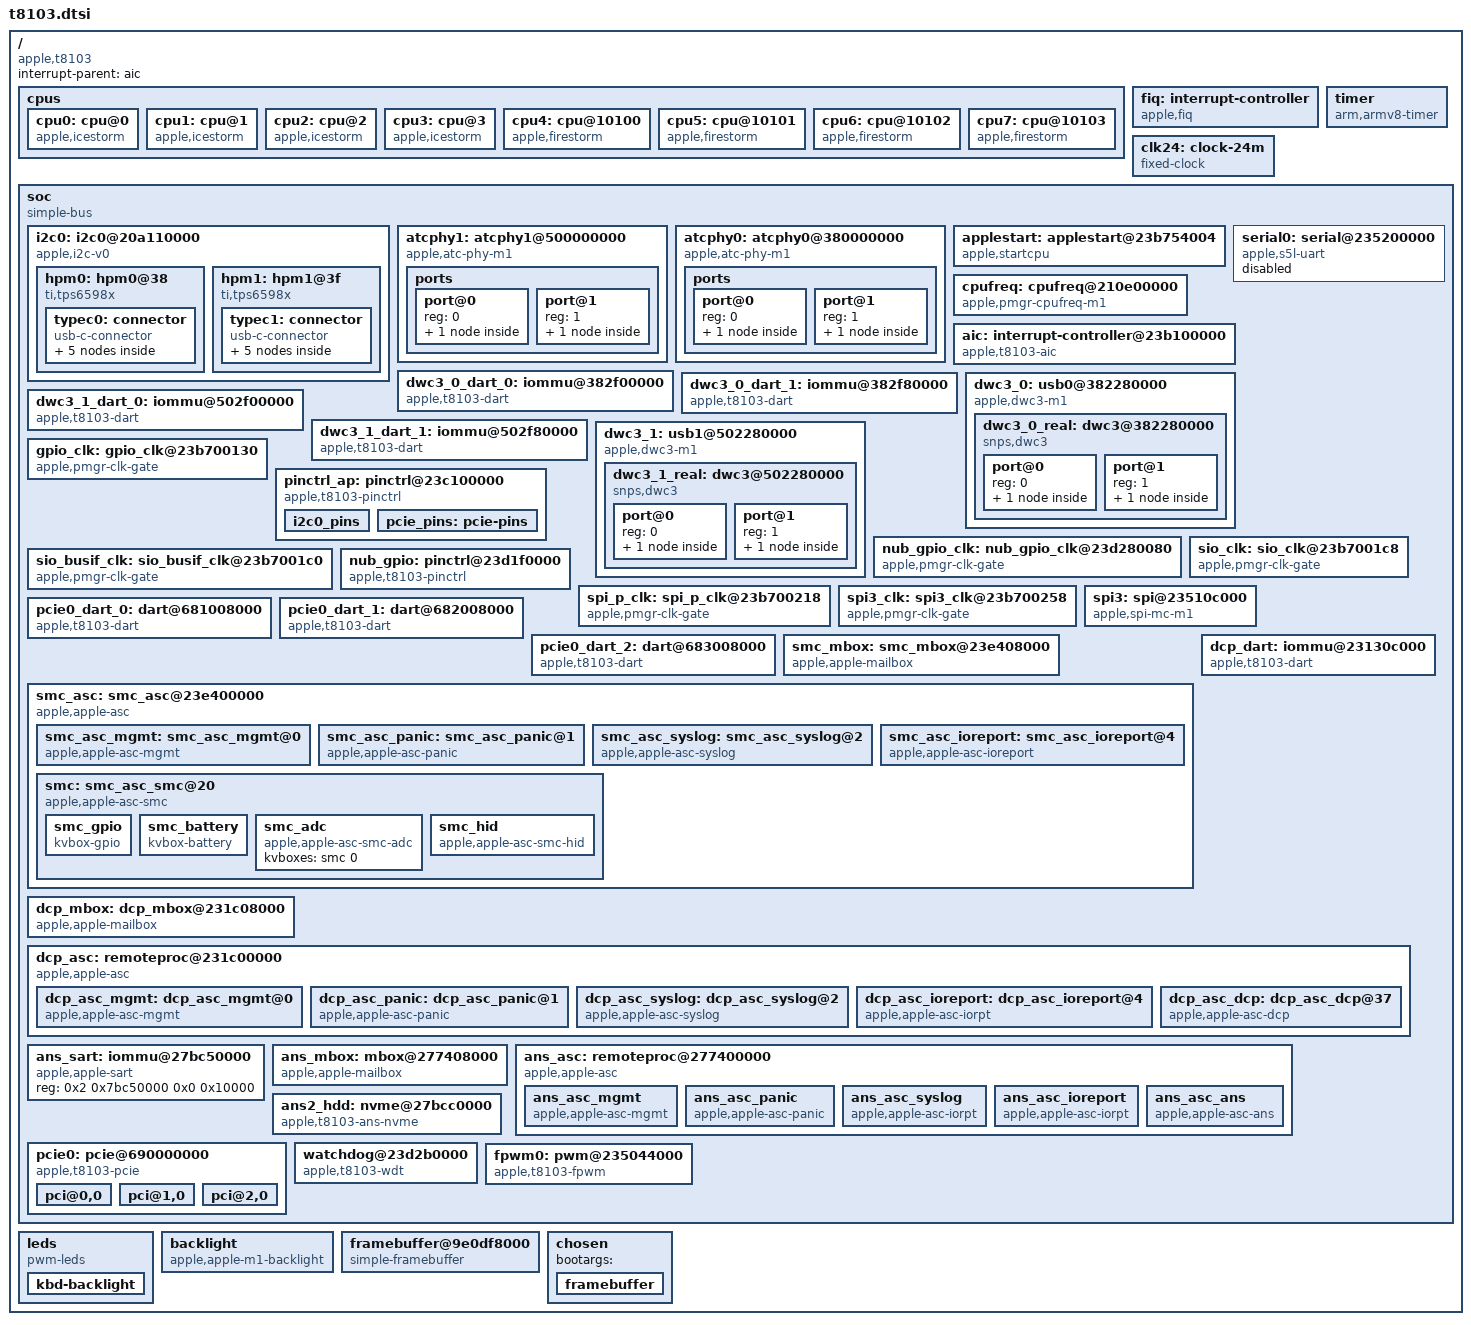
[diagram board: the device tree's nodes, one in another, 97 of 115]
// SPDX-License-Identifier: GPL-2.0+ OR MIT
/*
 * Apple T8103 "M1" SoC
 *
 * Other names: H13G, "Tonga"
 *
 * Copyright The Asahi Linux Contributors
 */

#include <dt-bindings/soc/ascii.h>
#include <dt-bindings/interrupt-controller/apple-aic.h>
#include <dt-bindings/interrupt-controller/irq.h>

#define APPLE_PINMUX(pin, func) ((pin) | ((func) << 16))
#define APPLE_PIN(pinmux) ((pinmux) & 0xffff)
#define APPLE_FUNC(pinmux) ((pinmux) >> 16)

/ {
	compatible = "apple,t8103", "apple,arm-platform";

	#address-cells = <2>;
	#size-cells = <2>;
	interrupt-parent = <&aic>;

	cpus {
		#address-cells = <1>;
		#size-cells = <0>;

		cpu0: cpu@0 {
			compatible = "apple,icestorm";
			device_type = "cpu";
			reg = <0x0>;
			enable-method = "apple,startcpu";
			cpu-release-addr = <0 0>; /* To be filled by loader */
			apple,cluster = <0>;
		};

		cpu1: cpu@1 {
			compatible = "apple,icestorm";
			device_type = "cpu";
			reg = <0x1>;
			enable-method = "apple,startcpu";
			cpu-release-addr = <0 0>; /* To be filled by loader */
			apple,cluster = <0>;
		};

		cpu2: cpu@2 {
			compatible = "apple,icestorm";
			device_type = "cpu";
			reg = <0x2>;
			enable-method = "apple,startcpu";
			cpu-release-addr = <0 0>; /* To be filled by loader */
			apple,cluster = <0>;
		};

		cpu3: cpu@3 {
			compatible = "apple,icestorm";
			device_type = "cpu";
			reg = <0x3>;
			enable-method = "apple,startcpu";
			cpu-release-addr = <0 0>; /* To be filled by loader */
			apple,cluster = <0>;
		};

		cpu4: cpu@10100 {
			compatible = "apple,firestorm";
			device_type = "cpu";
			reg = <0x10100>;
			enable-method = "apple,startcpu";
			cpu-release-addr = <0 0>; /* To be filled by loader */
			apple,cluster = <1>;
		};

		cpu5: cpu@10101 {
			compatible = "apple,firestorm";
			device_type = "cpu";
			reg = <0x10101>;
			enable-method = "apple,startcpu";
			cpu-release-addr = <0 0>; /* To be filled by loader */
			apple,cluster = <1>;
		};

		cpu6: cpu@10102 {
			compatible = "apple,firestorm";
			device_type = "cpu";
			reg = <0x10102>;
			enable-method = "apple,startcpu";
			cpu-release-addr = <0 0>; /* To be filled by loader */
			apple,cluster = <1>;
		};

		cpu7: cpu@10103 {
			compatible = "apple,firestorm";
			device_type = "cpu";
			reg = <0x10103>;
			enable-method = "apple,startcpu";
			cpu-release-addr = <0 0>; /* To be filled by loader */
			apple,cluster = <1>;
		};
	};

	fiq: interrupt-controller {
	        compatible = "apple,fiq";
		#interrupt-cells = <3>;
		interrupt-controller;
		use-for-ipi;
	};

	timer {
		compatible = "arm,armv8-timer";
		interrupt-parent = <&fiq>;
		interrupt-names = "phys", "virt", "hyp-phys", "hyp-virt";
		interrupts = <AIC_FIQ AIC_TMR_GUEST_PHYS IRQ_TYPE_LEVEL_HIGH>,
			     <AIC_FIQ AIC_TMR_GUEST_VIRT IRQ_TYPE_LEVEL_HIGH>,
			     <AIC_FIQ AIC_TMR_HV_PHYS IRQ_TYPE_LEVEL_HIGH>,
			     <AIC_FIQ AIC_TMR_HV_VIRT IRQ_TYPE_LEVEL_HIGH>;
	};

	clk24: clock-24m {
		compatible = "fixed-clock";
		#clock-cells = <0>;
		clock-frequency = <24000000>;
		clock-output-names = "clk24";
	};

	soc {
		compatible = "simple-bus";
		#address-cells = <2>;
		#size-cells = <2>;

		ranges;
		dma-ranges;
		nonposted-mmio;

		i2c0: i2c0@20a110000 {
			compatible = "apple,i2c-v0";
			reg = <0x2 0x35010000 0x0 0x4000>;
			interrupt-parent = <&aic>;
			interrupts = <0 627 4>;
			clocks = <&clk24>;
			pinctrl-0 = <&i2c0_pins>;
			pinctrl-names = "default";
			#address-cells = <0x1>;
			#size-cells = <0x0>;

			hpm0: hpm0@38 {
				compatible = "ti,tps6598x";
				reg = <0x38>;
				interrupt-parent = <&pinctrl_ap>;
				interrupts = <106 8>;

				no-long-writes;

				typec0: connector {
					compatible = "usb-c-connector";
					label = "USB-C B";
					power-role = "source";

					ports {
						#address-cells = <1>;
						#size-cells = <0>;
						port@0 {
							reg = <0>;
							typec0_con_hs: endpoint {
								remote-endpoint = <&typec0_usb_hs>;
							};
						};
						port@1 {
							reg = <1>;
							typec0_con_ss: endpoint {
								remote-endpoint = <&typec0_phy_ss>;
							};
						};
					};
				};
			};

			hpm1: hpm1@3f {
				compatible = "ti,tps6598x";
				reg = <0x3f>;
				interrupt-parent = <&pinctrl_ap>;
				interrupts = <106 8>;

				no-long-writes;

				typec1: connector {
					compatible = "usb-c-connector";
					label = "USB-C B";
					power-role = "source";

					ports {
						#address-cells = <1>;
						#size-cells = <0>;
						port@0 {
							reg = <0>;
							typec1_con_hs: endpoint {
								remote-endpoint = <&typec1_usb_hs>;
							};
						};
						port@1 {
							reg = <1>;
							typec1_con_ss: endpoint {
								remote-endpoint = <&typec1_phy_ss>;
							};
						};
					};
				};
			};
		};

		atcphy1: atcphy1@500000000 {
			compatible = "apple,atc-phy-m1";
			clocks = <&clk24>;
			reg = <0x5 0x00000000 0x0 0x1000000
				0x5 0x02000000 0x0 0x1080000>;
			#phy-cells = <0>;
			usb-role-switch;
			orientation-switch;
			mode-switch;
			accessory;
			#clock-cells = <0>;
			clock-output-names = "utmi1clk";

			ports {
				#address-cells = <1>;
				#size-cells = <0>;
				port@0 {
					reg = <0>;
					typec1_phy_ss: endpoint {
						phandle = <0x0e>;
					};
				};
				port@1 {
					reg = <1>;
					typec1_pipe_ss: endpoint {
						phandle = <0x2f>;
					};
				};
			};
		};


        atcphy0: atcphy0@380000000 {
            compatible = "apple,atc-phy-m1";
            clocks = <&clk24>;
            reg = <0x3 0x80000000 0x0 0x1000000
                   0x3 0x82000000 0x0 0x1080000>;
            #phy-cells = <0>;
            usb-role-switch;
            orientation-switch;
            mode-switch;
            accessory;
            #clock-cells = <0>;
            clock-output-names = "utmi0clk";

            ports {
                #address-cells = <1>;
                #size-cells = <0>;
                port@0 {
                    reg = <0>;
                    typec0_phy_ss: endpoint {
		    	phandle = <0x0f>;
                    };
                };
                port@1 {
                    reg = <1>;
                    typec0_pipe_ss: endpoint {
		    	phandle = <0x2e>;
                    };
                };
            };
        };
		applestart: applestart@23b754004 {
			compatible = "apple,startcpu";
			reg = <0x2 0x3b754004 0x0 0xc   0x2 0x10050000 0x0 0x8   0x2 0x10030fb0 0x0 0x4
				0x2 0x3b754004 0x0 0xc   0x2 0x10150000 0x0 0x8   0x2 0x10130fb0 0x0 0x4
				0x2 0x3b754004 0x0 0xc   0x2 0x10250000 0x0 0x8   0x2 0x10230fb0 0x0 0x4
				0x2 0x3b754004 0x0 0xc   0x2 0x10350000 0x0 0x8   0x2 0x10330fb0 0x0 0x4
				0x2 0x3b754004 0x0 0xc   0x2 0x11050000 0x0 0x8   0x2 0x11030fb0 0x0 0x4
				0x2 0x3b754004 0x0 0xc   0x2 0x11150000 0x0 0x8   0x2 0x11130fb0 0x0 0x4
				0x2 0x3b754004 0x0 0xc   0x2 0x11250000 0x0 0x8   0x2 0x11230fb0 0x0 0x4
				0x2 0x3b754004 0x0 0xc   0x2 0x11350000 0x0 0x8   0x2 0x11330fb0 0x0 0x4>;
		};

		cpufreq: cpufreq@210e00000 {
			compatible = "apple,pmgr-cpufreq-m1";
			reg = <0x2 0x10e00000 0x0 0x100000   0x2 0x11e00000 0x0 0x100000
				0x2 0x3b700000 0x0 0x100000   0x2 0x00200000 0x0 0x200000>;
			tunable-ecpu-states = <0x1aaaa 0x22c 0x1075f 0x26d 0xc031 0x2a6 0x963c 0x300 0x7c07 0x35b>;
			tunable-pcpu-states = <0x1aaaa 0x254 0x1352d 0x27d 0xf26c 0x2a3 0xc760 0x2a9 0xaaaa 0x2d1 0x9425 0x2e4 0x82e1 0x310 0x7537 0x320 0x6b33 0x342 0x62c3 0x377 0x5c5a 0x3a0 0x55ad 0x3d2 0x52af 0x3d2 0x516c 0x3d2 0x4fe6 0x3d2>;
			tunable-pcpu-fast-dcfg = <0x133 0x55555340>;
			tunable-pcpu-fast-freq = <0x888>;
		};

		serial0: serial@235200000 {
			compatible = "apple,s5l-uart";
			reg = <0x2 0x35200000 0x0 0x1000>;
			reg-io-width = <4>;
			interrupt-parent = <&aic>;
			interrupts = <AIC_IRQ 605 IRQ_TYPE_LEVEL_HIGH>;
			/*
			 * TODO: figure out the clocking properly, there may
			 * be a third selectable clock.
			 */
			clocks = <&clk24>, <&clk24>;
			clock-names = "uart", "clk_uart_baud0";
			status = "disabled";
		};

		aic: interrupt-controller@23b100000 {
			compatible = "apple,t8103-aic";
			#interrupt-cells = <3>;
			interrupt-controller;
			reg = <0x2 0x3b100000 0x0 0x8000>;
		};

		dwc3_0_dart_0: iommu@382f00000 {
			compatible = "apple,t8103-dart";
			reg = <0x3 0x82f00000 0x0 0x4000>;
			interrupt-parent = <&aic>;
			interrupts = <AIC_IRQ 781 IRQ_TYPE_LEVEL_HIGH>;
			#iommu-cells = <1>;
		};

		dwc3_0_dart_1: iommu@382f80000 {
			compatible = "apple,t8103-dart";
			reg = <0x3 0x82f80000 0x0 0x4000>;
			interrupt-parent = <&aic>;
			interrupts = <AIC_IRQ 781 IRQ_TYPE_LEVEL_HIGH>;
			#iommu-cells = <1>;
		};

		dwc3_0: usb0@382280000 {
			compatible = "apple,dwc3-m1";
			reg = <0x3 0x80000000 0x0 0x100000 0x3 0x82000000 0x0 0x1000000>;
			#address-cells = <2>;
			#size-cells = <2>;
			ranges;
			nonposted-mmio;
			usb-role-switch;

			dwc3_0_real: dwc3@382280000 {
				compatible = "snps,dwc3";
				reg = <0x3 0x82280000 0x0 0x100000>;
				interrupt-parent = <&aic>;
				interrupts = <AIC_IRQ 777 IRQ_TYPE_LEVEL_HIGH>;
				usb-role-switch;
				iommus = <&dwc3_0_dart_0 0>, <&dwc3_0_dart_1 1>;
				port@0 {
					reg = <0>;
					typec0_usb_hs: endpoint {
						remote-endpoint = <&typec0_con_hs>;
					};
				};
				port@1 {
					reg = <1>;
					typec0_usb_ss: endpoint {
						remote-endpoint = <&typec0_pipe_ss>;
					};
				};
			};
		};

		dwc3_1_dart_0: iommu@502f00000 {
			compatible = "apple,t8103-dart";
			reg = <0x5 0x02f00000 0x0 0x4000>;
			interrupt-parent = <&aic>;
			interrupts = <AIC_IRQ 861 IRQ_TYPE_LEVEL_HIGH>;
			#iommu-cells = <1>;
		};

		dwc3_1_dart_1: iommu@502f80000 {
			compatible = "apple,t8103-dart";
			reg = <0x5 0x02f80000 0x0 0x4000>;
			interrupt-parent = <&aic>;
			interrupts = <AIC_IRQ 861 IRQ_TYPE_LEVEL_HIGH>;
			#iommu-cells = <1>;
		};

		dwc3_1: usb1@502280000 {
			compatible = "apple,dwc3-m1";
			reg = <0x5 0x00000000 0x0 0x100000 0x5 0x02000000 0x0 0x1000000>;
			#address-cells = <2>;
			#size-cells = <2>;
			ranges;
			nonposted-mmio;
			usb-role-switch;

			dwc3_1_real: dwc3@502280000 {
				compatible = "snps,dwc3";
				reg = <0x5 0x02280000 0x0 0x100000>;
				interrupt-parent = <&aic>;
				interrupts = <AIC_IRQ 857 IRQ_TYPE_LEVEL_HIGH>;
				iommus = <&dwc3_1_dart_0 0>, <&dwc3_1_dart_1 1>;
				usb-role-switch;
				port@0 {
					reg = <0>;
					typec1_usb_hs: endpoint {
						remote-endpoint = <&typec1_con_hs>;
					};
				};
				port@1 {
					reg = <1>;
					typec1_usb_ss: endpoint {
						remote-endpoint = <&typec1_pipe_ss>;
					};
				};
			};
		};

		gpio_clk: gpio_clk@23b700130 {
		    compatible = "apple,pmgr-clk-gate";
		    #clock-cells = <0>;
		    reg = <0x2 0x3b700130 0x0 0x8>;
		    clocks = <&clk24>;
		    clock-output-names = "gpio_clk";
		};

		pinctrl_ap: pinctrl@23c100000 {
			compatible = "apple,t8103-pinctrl", "apple,pinctrl";
			reg = <0x2 0x3c100000 0x0 0x100000>;
		    pin-count = <212>;

		    interrupts = <0 190 4   0 191 4   0 192 4   0 193 4   0 194 4   0 195 4   0 196 4>;

		    clocks = <&gpio_clk>;

		    gpio-controller;
		    #gpio-cells = <2>;
		    gpio-ranges = <&pinctrl_ap 0 0 212>;

                    interrupt-parent = <&aic>;
		    interrupt-controller;
		    #interrupt-cells = <2>;

		    i2c0_pins: i2c0_pins {
		        pinmux = <APPLE_PINMUX(192, 1) APPLE_PINMUX(188, 1)>;
		    };

			pcie_pins: pcie-pins {
				pinmux = <APPLE_PINMUX(150, 1)>,
					 <APPLE_PINMUX(151, 1)>,
					 <APPLE_PINMUX(32, 1)>;
			};
		};

		nub_gpio_clk: nub_gpio_clk@23d280080 {
		    compatible = "apple,pmgr-clk-gate";
		    #clock-cells = <0>;
		    reg = <0x2 0x3d280080 0x0 0x8>;
		    clocks = <&clk24>;
		    clock-output-names = "nub_gpio_clk";
		};

		sio_busif_clk: sio_busif_clk@23b7001c0 {
			compatible = "apple,pmgr-clk-gate";
			#clock-cells = <0>;
			reg = <0x2 0x3b7001c0 0x0 0x8>;
			clocks = <&clk24>;
			clock-output-names = "sio_busif_clk";
		};

		sio_clk: sio_clk@23b7001c8 {
			compatible = "apple,pmgr-clk-gate";
			#clock-cells = <0>;
			reg = <0x2 0x3b7001c8 0x0 0x8>;
			clocks = <&sio_busif_clk>;
			clock-output-names = "sio_clk";
		};

		nub_gpio: pinctrl@23d1f0000 {
		    compatible = "apple,t8103-pinctrl", "apple,pinctrl";
		    reg = <0x2 0x3d1f0000 0x0 0x4000>;

			interrupts = <AIC_IRQ 330 IRQ_TYPE_LEVEL_HIGH
			              AIC_IRQ 331 IRQ_TYPE_LEVEL_HIGH
			              AIC_IRQ 332 IRQ_TYPE_LEVEL_HIGH
			              AIC_IRQ 333 IRQ_TYPE_LEVEL_HIGH
			              AIC_IRQ 334 IRQ_TYPE_LEVEL_HIGH
			              AIC_IRQ 335 IRQ_TYPE_LEVEL_HIGH
			              AIC_IRQ 336 IRQ_TYPE_LEVEL_HIGH>;

		    clocks = <&nub_gpio_clk>;

		    gpio-controller;
		    #gpio-cells = <2>;
		    gpio-ranges = <&nub_gpio 0 221 23>;

                    interrupt-parent = <&aic>;
		    interrupt-controller;
		    #interrupt-cells = <2>;
		};

		spi_p_clk: spi_p_clk@23b700218 {
		    compatible = "apple,pmgr-clk-gate";
		    #clock-cells = <0>;
		    reg = <0x2 0x3b700218 0x0 0x8>;
		    clocks = <&sio_clk>;
		    clock-output-names = "spi_p_clk";
		};

		spi3_clk: spi3_clk@23b700258 {
		    compatible = "apple,pmgr-clk-gate";
		    #clock-cells = <0>;
		    reg = <0x2 0x3b700258 0x0 0x8>;
		    clocks = <&spi_p_clk>;
		    clock-output-names = "spi3_clk";
		};

		spi3: spi@23510c000 {
		    compatible = "apple,spi-mc-m1";
		    reg = <0x2 0x3510c000 0x0 0x4000>;
		    interrupts = <0 617 4>;
		    //clocks = <&spi3_clk>;
                    interrupt-parent = <&aic>;
                    clocks = <&clk24>;
		    cs-gpios = <&pinctrl_ap 49 0>;
		    #address-cells = <1>;
		    #size-cells = <0>;
		};

		pcie0_dart_0: dart@681008000 {
			compatible = "apple,t8103-dart";
			reg = <0x6 0x81008000 0x0 0x4000>;
			#iommu-cells = <1>;
			interrupt-parent = <&aic>;
			interrupts = <AIC_IRQ 696 IRQ_TYPE_LEVEL_HIGH>;
		};

		pcie0_dart_1: dart@682008000 {
			compatible = "apple,t8103-dart";
			reg = <0x6 0x82008000 0x0 0x4000>;
			#iommu-cells = <1>;
			interrupt-parent = <&aic>;
			interrupts = <AIC_IRQ 699 IRQ_TYPE_LEVEL_HIGH>;
		};

		pcie0_dart_2: dart@683008000 {
			compatible = "apple,t8103-dart";
			reg = <0x6 0x83008000 0x0 0x4000>;
			#iommu-cells = <1>;
			interrupt-parent = <&aic>;
			interrupts = <AIC_IRQ 702 IRQ_TYPE_LEVEL_HIGH>;
		};

		smc_mbox: smc_mbox@23e408000 {
		        compatible = "apple,apple-mailbox";
			reg = <0x2 0x3e408000 0 0x4000>;
			#mbox-cells = <1>; /* could be 0, but that requires extra code */
			interrupt-parent = <&aic>;
			interrupts = <0 400 4  0 403 4>;
		};

		smc_asc: smc_asc@23e400000 {
		        compatible = "apple,apple-asc";
			reg = <0x2 0x3e400000 0 0x8000>;
			rproc-name = "smc";
			mboxes = <&smc_mbox 0>;
			#mbox-cells = <1>;
			endpoints = <0>;
			smc_asc_mgmt: smc_asc_mgmt@0 {
				compatible = "apple,apple-asc-mgmt", "apple,apple-asc-system-endpoint";
				mboxes = <&smc_asc 0x0>;
				rprocs = <&smc_asc>;
			};
			smc_asc_panic: smc_asc_panic@1 {
				compatible = "apple,apple-asc-panic", "apple,apple-asc-system-endpoint";
				mboxes = <&smc_asc 0x1>;
				rprocs = <&smc_asc>;
			};
			smc_asc_syslog: smc_asc_syslog@2 {
				compatible = "apple,apple-asc-syslog", "apple,apple-asc-system-endpoint";
				mboxes = <&smc_asc 0x2>;
				rprocs = <&smc_asc>;
			};
			smc_asc_ioreport: smc_asc_ioreport@4 {
				compatible = "apple,apple-asc-ioreport", "apple,apple-asc-system-endpoint";
				mboxes = <&smc_asc 0x4>;
				rprocs = <&smc_asc>;
			};
			smc: smc_asc_smc@20 {
			        compatible = "apple,apple-asc-smc";
				mboxes = <&smc_asc 0x20>;
				rprocs = <&smc_asc>;
				#address-cells = <1>;
				#size-cells = <1>;
				#kvbox-cells = <1>;
				#mbox-cells = <1>;
				smc_gpio: smc_gpio {
					pin-count = <2>;
					pin-prefix = "smc";
					compatible = "kvbox-gpio";
					kvboxes = <&smc 0>;
					kvbox-keys = "gP0d", "gP12";
					kvbox-read-suffix = /bits/ 8 <0x01 0x00 0x00 0x00>;
					kvbox-write-enable = /bits/ 8 <0x01 0x00 0x80 0x00>;
					kvbox-write-disable = /bits/ 8 <0x00 0x00 0x00 0x00>;
					gpio-line-names = "gP0d", "gP12";
				        gpio-controller;
					#gpio-cells = <2>;

#define SMC_IRQ_BATT 0
#define SMC_IRQ_HID 1

#define SMC_PIN(a,b,c,d,description) \
	pin_##a##b##c##d { \
		gpio-line-name = description; \
	        key-read = /bits/ 8 <ASCII_##d ASCII_##c ASCII_##b ASCII_##a 0x01 0x00 0x00 0x00>; \
	        key-write = /bits/ 8 <ASCII_##d ASCII_##c ASCII_##b ASCII_##a>; \
	        data-enable = /bits/ 8 <0x01 0x00 0x00 0x00>; \
	        data-disable = /bits/ 8 <0x00 0x00 0x00 0x00>; \
	}
	     		      		SMC_PIN(g,P,0,d,"PCI power");
					SMC_PIN(g,P,1,2,"backlight power");
				};
				smc_battery {
					compatible = "kvbox-battery";
					mboxes = <&smc 1>;
					kvboxes = <&smc 0>;

					capacity-prop = <FOURCC(S,B,A,S)>;
				};
				smc_adc {
					compatible = "apple,apple-asc-smc-adc";
					kvboxes = <&smc 0>;
					#kvbox-cells = <1>;
				};
				smc_hid {
					compatible = "apple,apple-asc-smc-hid";
					mboxes = <&smc 0>;
					kvboxes = <&smc 0>;
				};
			};
		};

		dcp_mbox: dcp_mbox@231c08000 {
		        compatible = "apple,apple-mailbox";
			reg = <0x2 0x31c08000 0 0x4000>;
			#mbox-cells = <1>; /* could be 0, but that requires extra code */
			interrupt-parent = <&aic>;
			interrupts = <0 0x1ab 4  0 0x1ae 4>;
		};

		dcp_dart: iommu@23130c000 {
			compatible = "apple,t8103-dart";
			reg = <0x2 0x3130c000 0 0x4000>;
			interrupt-parent = <&aic>;
			interrupts = <AIC_IRQ 0x1bd IRQ_TYPE_LEVEL_HIGH>;
			#iommu-cells = <1>;
		};

		dcp_asc: remoteproc@231c00000 {
		        compatible = "apple,apple-asc";
			reg = <0x2 0x31c00000 0 0x8000>;
			rproc-name = "dcp";
			iommus = <&dcp_dart 15>;
			mboxes = <&dcp_mbox 0>;
			#mbox-cells = <1>;
			endpoints = <0>;
			dcp_asc_mgmt: dcp_asc_mgmt@0 {
				compatible = "apple,apple-asc-mgmt", "apple,apple-asc-system-endpoint";
				mboxes = <&dcp_asc 0x0>;
				rprocs = <&dcp_asc>;
				iommus = <&dcp_dart 15>;
			};
			dcp_asc_panic: dcp_asc_panic@1 {
				compatible = "apple,apple-asc-panic", "apple,apple-asc-system-endpoint";
				mboxes = <&dcp_asc 0x1>;
				rprocs = <&dcp_asc>;
				iommus = <&dcp_dart 15>;
			};
			dcp_asc_syslog: dcp_asc_syslog@2 {
				compatible = "apple,apple-asc-syslog", "apple,apple-asc-system-endpoint";
				mboxes = <&dcp_asc 0x2>;
				rprocs = <&dcp_asc>;
				iommus = <&dcp_dart 15>;
			};
			dcp_asc_ioreport: dcp_asc_ioreport@4 {
				compatible = "apple,apple-asc-iorpt", "apple,apple-asc-system-endpoint";
				mboxes = <&dcp_asc 0x4>;
				rprocs = <&dcp_asc>;
				iommus = <&dcp_dart 15>;
			};
			dcp_asc_dcp: dcp_asc_dcp@37 {
				compatible = "apple,apple-asc-dcp", "apple,apple-asc-system-endpoint";
				mboxes = <&dcp_asc 0x37>;
				rprocs = <&dcp_asc>;
				#mbox-cells = <1>; /* could be 0, but requires extra code */
				iommus = <&dcp_dart 15>;
			};
		};

		ans_sart: iommu@27bc50000 {
			compatible = "apple,apple-sart";
			reg = <0x2 0x7bc50000 0x0 0x10000>;
			#iommu-cells = <1>;
		};

		ans_mbox: mbox@277408000 {
			compatible = "apple,apple-mailbox";
			reg = <0x2 0x77408000 0x0 0x8000>;
			interrupt-parent = <&aic>;
			interrupts = <AIC_IRQ 583 IRQ_TYPE_LEVEL_HIGH>, <AIC_IRQ 586 IRQ_TYPE_LEVEL_HIGH>;
			#mbox-cells = <1>; /* could be 0, but requires extra code */
			/* HACK alert: we don't go through the SART, ans_asc does, but the SART doesn't implement a proper iommu, just a startup function... */
			iommus = <&ans_sart 0>;
		};

		ans_asc: remoteproc@277400000 {
		        compatible = "apple,apple-asc";
			reg = <0x2 0x77400000 0 0x8000>;
			rproc-name = "ans";
			mboxes = <&ans_mbox 0>;
			#mbox-cells = <1>;
			endpoints = <0>;
			#address-cells = <2>;
			#size-cells = <2>;
			ans_asc_mgmt: ans_asc_mgmt {
				compatible = "apple,apple-asc-mgmt", "apple,apple-asc-system-endpoint";
				mboxes = <&ans_asc 0x0>;
				rprocs = <&ans_asc>;
			};
			ans_asc_panic: ans_asc_panic {
				compatible = "apple,apple-asc-panic", "apple,apple-asc-system-endpoint";
				mboxes = <&ans_asc 0x1>;
				rprocs = <&ans_asc>;
			};
			ans_asc_syslog: ans_asc_syslog {
				compatible = "apple,apple-asc-iorpt", "apple,apple-asc-system-endpoint";
				mboxes = <&ans_asc 0x2>;
				rprocs = <&ans_asc>;
			};
			ans_asc_ioreport: ans_asc_ioreport {
				compatible = "apple,apple-asc-iorpt", "apple,apple-asc-system-endpoint";
				mboxes = <&ans_asc 0x4>;
				rprocs = <&ans_asc>;
			};
			ans_asc_ans: ans_asc_ans {
				compatible = "apple,apple-asc-ans", "apple,apple-asc-system-endpoint";
				mboxes = <&ans_asc 0x20>;
				#mbox-cells = <1>;
				rprocs = <&ans_asc>;
			};
		};
		ans2_hdd: nvme@27bcc0000 {
                        compatible = "apple,t8103-ans-nvme";
                        reg = <0x2 0x7bcc0000 0x0 0x40000>;
                        interrupt-parent = <&aic>;
                        interrupts = <AIC_IRQ 590 IRQ_TYPE_LEVEL_HIGH>;
		        mboxes = <&ans_asc_ans 0>;
                };


		pcie0: pcie@690000000 {
			compatible = "apple,t8103-pcie", "apple,pcie";
			device_type = "pci";

			reg = <0x6 0x90000000 0x0 0x1000000>,
			      <0x6 0x80000000 0x0 0x100000>,
			      <0x6 0x81000000 0x0 0x4000>,
			      <0x6 0x82000000 0x0 0x4000>,
			      <0x6 0x83000000 0x0 0x4000>,
			      <0x6 0x80080000 0x0 0x90000>;
			reg-names = "config", "rc", "port0", "port1", "port2";

			interrupt-parent = <&aic>;
			interrupts = <AIC_IRQ 695 IRQ_TYPE_LEVEL_HIGH>,
				     <AIC_IRQ 698 IRQ_TYPE_LEVEL_HIGH>,
				     <AIC_IRQ 701 IRQ_TYPE_LEVEL_HIGH>,
				     <AIC_IRQ 704 IRQ_TYPE_LEVEL_HIGH>,
				     <AIC_IRQ 705 IRQ_TYPE_LEVEL_HIGH>,
				     <AIC_IRQ 706 IRQ_TYPE_LEVEL_HIGH>,
				     <AIC_IRQ 707 IRQ_TYPE_LEVEL_HIGH>,
				     <AIC_IRQ 708 IRQ_TYPE_LEVEL_HIGH>,
				     <AIC_IRQ 709 IRQ_TYPE_LEVEL_HIGH>,
				     <AIC_IRQ 710 IRQ_TYPE_LEVEL_HIGH>,
				     <AIC_IRQ 711 IRQ_TYPE_LEVEL_HIGH>,
				     <AIC_IRQ 712 IRQ_TYPE_LEVEL_HIGH>,
				     <AIC_IRQ 713 IRQ_TYPE_LEVEL_HIGH>,
				     <AIC_IRQ 714 IRQ_TYPE_LEVEL_HIGH>,
				     <AIC_IRQ 715 IRQ_TYPE_LEVEL_HIGH>,
				     <AIC_IRQ 716 IRQ_TYPE_LEVEL_HIGH>,
				     <AIC_IRQ 717 IRQ_TYPE_LEVEL_HIGH>,
				     <AIC_IRQ 718 IRQ_TYPE_LEVEL_HIGH>,
				     <AIC_IRQ 719 IRQ_TYPE_LEVEL_HIGH>,
				     <AIC_IRQ 720 IRQ_TYPE_LEVEL_HIGH>,
				     <AIC_IRQ 721 IRQ_TYPE_LEVEL_HIGH>,
				     <AIC_IRQ 722 IRQ_TYPE_LEVEL_HIGH>,
				     <AIC_IRQ 723 IRQ_TYPE_LEVEL_HIGH>,
				     <AIC_IRQ 724 IRQ_TYPE_LEVEL_HIGH>,
				     <AIC_IRQ 725 IRQ_TYPE_LEVEL_HIGH>,
				     <AIC_IRQ 726 IRQ_TYPE_LEVEL_HIGH>,
				     <AIC_IRQ 727 IRQ_TYPE_LEVEL_HIGH>,
				     <AIC_IRQ 728 IRQ_TYPE_LEVEL_HIGH>,
				     <AIC_IRQ 729 IRQ_TYPE_LEVEL_HIGH>,
				     <AIC_IRQ 730 IRQ_TYPE_LEVEL_HIGH>,
				     <AIC_IRQ 731 IRQ_TYPE_LEVEL_HIGH>,
				     <AIC_IRQ 732 IRQ_TYPE_LEVEL_HIGH>,
				     <AIC_IRQ 733 IRQ_TYPE_LEVEL_HIGH>,
				     <AIC_IRQ 734 IRQ_TYPE_LEVEL_HIGH>,
				     <AIC_IRQ 735 IRQ_TYPE_LEVEL_HIGH>;

			msi-controller;
			msi-parent = <&pcie0>;
			msi-ranges = <704 32>;

			iommu-map = <0x100 &pcie0_dart_0 0 1>,
				    <0x200 &pcie0_dart_1 0 1>,
				    <0x300 &pcie0_dart_2 0 1>;
			iommu-map-mask = <0xff00>;

			bus-range = <0 3>;
			#address-cells = <3>;
			#size-cells = <2>;
			ranges = <0x43000000 0x6 0xa0000000 0x6 0xa0000000 0x0 0x20000000>,
				 <0x02000000 0x0 0xc0000000 0x6 0xc0000000 0x0 0x40000000>;

			pinctrl-0 = <&pcie_pins>;
			pinctrl-names = "default";

			reset-gpios = <&pinctrl_ap 152 0
				       &pinctrl_ap 153 0
				       &pinctrl_ap 33 0>;

			pci@0,0 {
				device_type = "pci";
				reg = <0x0 0x0 0x0 0x0 0x0>;
				reset-gpios = <&pinctrl_ap 152 0>;
				max-link-speed = <2>;

				#address-cells = <3>;
				#size-cells = <2>;
				ranges;
			};

			pci@1,0 {
				device_type = "pci";
				reg = <0x800 0x0 0x0 0x0 0x0>;
				reset-gpios = <&pinctrl_ap 153 0>;
				max-link-speed = <2>;

				#address-cells = <3>;
				#size-cells = <2>;
				ranges;
			};

			pci@2,0 {
				device_type = "pci";
				reg = <0x1000 0x0 0x0 0x0 0x0>;
				reset-gpios = <&pinctrl_ap 33 0>;
				max-link-speed = <1>;

				#address-cells = <3>;
				#size-cells = <2>;
				ranges;
			};
		};

		watchdog@23d2b0000 {
			compatible = "apple,t8103-wdt";
			reg = <0x2 0x3d2b0000 0x0 0x4000>;
			clocks = <&clk24>;
		};

		fpwm0: pwm@235044000 {
			compatible = "apple,t8103-fpwm";
			reg = <0x2 0x35044000 0x0 0x4000>;
			clocks = <&clk24>;
			#pwm-cells = <2>;
		};
	};

	leds {
		compatible = "pwm-leds";

		kbd-backlight {
			label = "kbd_backlight";
			function = LED_FUNCTION_KBD_BACKLIGHT;
			color = <LED_COLOR_ID_WHITE>;
			pwm-names = "kbd_backlight";
			pwms = <&fpwm0 0 1000000>;
			max-brightness = <255>;
		};
	};


	backlight: backlight {
		compatible = "apple,apple-m1-backlight";
		max-brightness = <0x20d0000>;
		mboxes = <&dcp_asc_dcp 0>;
		power-gpios = <&smc_gpio 1 0>;
	};

	framebuffer@9e0df8000 {
		#address-cells = <0x02>;
		#size-cells = <0x02>;
		compatible = "simple-framebuffer";
		reg = <0 0 0 0>;
		format = "x8r8g8b8";
		height = <0>;
		stride = <0>;
		width = <0>;
		status = "okay";
	};

	chosen {
	        bootargs = "";
		framebuffer { };
	};
};
